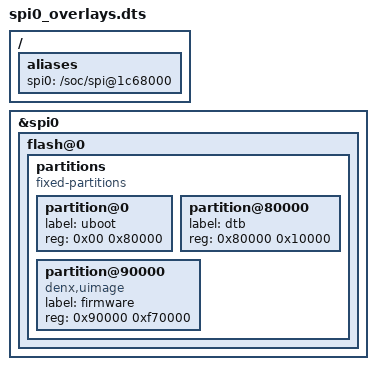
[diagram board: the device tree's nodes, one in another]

/ {
	aliases {
		spi0 = "/soc/spi@1c68000";
	};
};

&spi0 {
	status = "okay";

	flash@0 {
		partitions: partitions {
			compatible = "fixed-partitions";
			#address-cells = <0x01>;
			#size-cells = <0x01>;

			partition@0 {
				label = "uboot";
				reg = <0x00 0x80000>;
			};

			partition@80000 {
				label = "dtb";
				reg = <0x80000 0x10000>;
			};

			partition@90000 {
				compatible = "denx,uimage";
				label = "firmware";
				reg = <0x90000 0xf70000>;
			};
		};
	};
};
